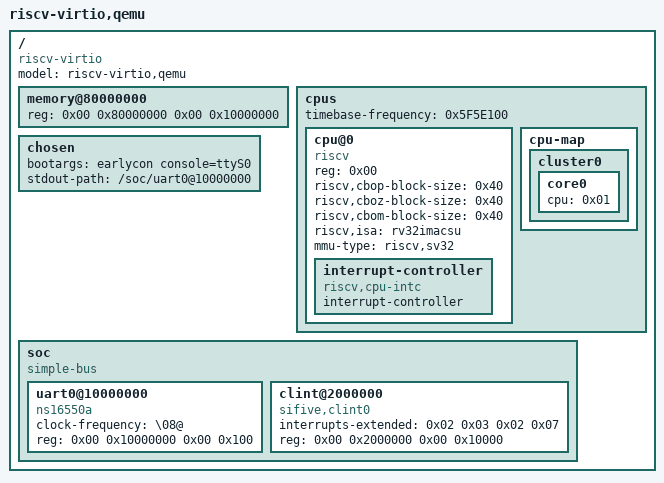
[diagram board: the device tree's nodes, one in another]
/dts-v1/;

/ {
    #address-cells = <0x02>;
    #size-cells = <0x02>;
	compatible = "riscv-virtio";
	model = "riscv-virtio,qemu";

    
	memory@80000000 {
		device_type = "memory";
		reg = <0x00 0x80000000 0x00 0x10000000>;
	};

    cpus {
		#address-cells = <0x01>;
		#size-cells = <0x00>;
		timebase-frequency = <0x5F5E100>;

        cpu@0 {
            phandle = <0x01>;
            device_type = "cpu";
            reg = <0x00>;
            status = "okay";
            compatible = "riscv";
            riscv,cbop-block-size = <0x40>;
			riscv,cboz-block-size = <0x40>;
			riscv,cbom-block-size = <0x40>;
            riscv,isa = "rv32imacsu";
			mmu-type = "riscv,sv32";

			interrupt-controller {
				#interrupt-cells = <0x01>;
				interrupt-controller;
				compatible = "riscv,cpu-intc";
				phandle = <0x02>;
			};
        };

        cpu-map {
			cluster0 {
				core0 {
					cpu = <0x01>;
				};
			};
		};
    };

    chosen {
		bootargs = "earlycon console=ttyS0";
		stdout-path = "/soc/uart0@10000000";
	};

    soc {
        #address-cells = <0x02>;
        #size-cells = <0x02>;
    	compatible = "simple-bus";
		ranges;

        uart0@10000000 {
			clock-frequency = "\08@";           
			reg = <0x00 0x10000000 0x00 0x100>;
			compatible = "ns16550a";
        };

		clint@2000000 {
			interrupts-extended = <0x02 0x03 0x02 0x07>;
			reg = <0x00 0x2000000 0x00 0x10000>;
			compatible = "sifive,clint0\0riscv,clint0";
		};
    };
};
